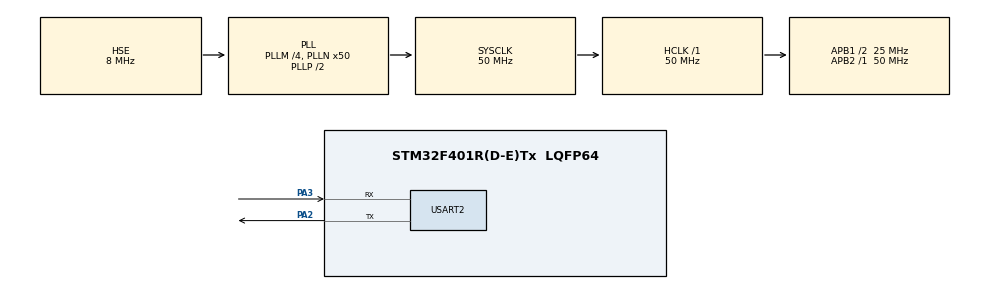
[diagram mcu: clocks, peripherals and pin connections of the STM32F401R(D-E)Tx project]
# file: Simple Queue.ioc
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FREERTOS.Tasks01=defaultTask,0,128,StartDefaultTask,Default,NULL,Dynamic,NULL,NULL
Mcu.Family=STM32F4
Mcu.Name=STM32F401R(D-E)Tx
Mcu.Package=LQFP64
NVIC.PriorityGroup=NVIC_PRIORITYGROUP_4
NVIC.TIM5_IRQn=true\:15\:0\:false\:false\:true\:false\:false\:true\:true
NVIC.TimeBase=TIM5_IRQn
NVIC.TimeBaseIP=TIM5
NVIC.USART2_IRQn=true\:5\:0\:false\:false\:true\:true\:true\:true\:true
PA2.Mode=Asynchronous
PA2.Signal=USART2_TX
PA3.Mode=Asynchronous
PA3.Signal=USART2_RX
PH0\ -\ OSC_IN.Mode=HSE-External-Oscillator
PH0\ -\ OSC_IN.Signal=RCC_OSC_IN
PH1\ -\ OSC_OUT.Mode=HSE-External-Oscillator
PH1\ -\ OSC_OUT.Signal=RCC_OSC_OUT
ProjectManager.HeapSize=0x200
ProjectManager.StackSize=0x400
ProjectManager.TargetToolchain=STM32CubeIDE
RCC.48MHZClocksFreq_Value=25000000
RCC.AHBFreq_Value=50000000
RCC.APB1CLKDivider=RCC_HCLK_DIV2
RCC.APB1Freq_Value=25000000
RCC.APB1TimFreq_Value=50000000
RCC.APB2Freq_Value=50000000
RCC.APB2TimFreq_Value=50000000
RCC.CortexFreq_Value=50000000
RCC.HCLKFreq_Value=50000000
RCC.HSE_VALUE=8000000
RCC.HSI_VALUE=16000000
RCC.LSE_VALUE=32768
RCC.PLLM=4
RCC.PLLN=50
RCC.PLLSourceVirtual=RCC_PLLSOURCE_HSE
RCC.SYSCLKFreq_VALUE=50000000
RCC.SYSCLKSource=RCC_SYSCLKSOURCE_PLLCLK
RCC.VCOOutputFreq_Value=100000000
USART2.VirtualMode=VM_ASYNC
VP_FREERTOS_VS_CMSIS_V1.Mode=CMSIS_V1
VP_SYS_VS_tim5.Mode=TIM5
board=custom

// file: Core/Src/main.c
/* USER CODE BEGIN Header */
/**
 ******************************************************************************
 * @file           : main.c
 * @brief          : Main program body
 ******************************************************************************
 * @attention
 *
 * Copyright (c) 2025 STMicroelectronics.
 * All rights reserved.
 *
 * This software is licensed under terms that can be found in the LICENSE file
 * in the root directory of this software component.
 * If no LICENSE file comes with this software, it is provided AS-IS.
 *
 ******************************************************************************
 */
/* USER CODE END Header */
#include "main.h"
//#include "cmsis_os.h"

/* USER CODE BEGIN Includes */
#include "FreeRTOS.h"
#include "task.h"
#include "timers.h"
#include "queue.h"
#include "semphr.h"
#include "event_groups.h"

#include "string.h"
#include "stdio.h"
/* USER CODE END Includes */

UART_HandleTypeDef huart2;

/* USER CODE BEGIN PV */
uint8_t Rx_data;
/* USER CODE END PV */

void SystemClock_Config(void);
static void MX_GPIO_Init(void);
static void MX_USART2_UART_Init(void);

xTaskHandle Sender_HPT_Handler;
xTaskHandle Sender_LPT_Handler;
xTaskHandle Receiver_Handler;

/**************** QUEUE HANDLER ***********************/
xQueueHandle SimpleQueue;

void Sender_HPT_Task (void *argument);
void Sender_LPT_Task (void *argument);
void Receiver_Task (void *argument);
int main(void)
{

	/* MCU Configuration--------------------------------------------------------*/

	/* Reset of all peripherals, Initializes the Flash interface and the Systick. */
	HAL_Init();

	/* USER	 CODE BEGIN Init */

	/* USER CODE END Init */

	/* Configure the system clock */
	SystemClock_Config();

	/* Initialize all configured peripherals */
	MX_GPIO_Init();
	MX_USART2_UART_Init();
	/************************* Create Integer Queue ****************************/
	SimpleQueue = xQueueCreate(5, sizeof (int));
	if (SimpleQueue == 0)  // Queue not created
	{
		char *str = "Unable to create Integer Queue\n\n";
		HAL_UART_Transmit(&huart2, (uint8_t *)str, strlen (str), HAL_MAX_DELAY);
	}
	else
	{
		char *str = "Integer Queue Created successfully\n\n";
		HAL_UART_Transmit(&huart2, (uint8_t *)str, strlen (str), HAL_MAX_DELAY);
	}
	/* We should never get here as control is now taken by the scheduler */
	xTaskCreate(Sender_HPT_Task, "HPT_SEND", 128, NULL, 3, &Sender_HPT_Handler);
	xTaskCreate(Sender_LPT_Task, "LPT_SEND", 128, (void *)111, 2, &Sender_LPT_Handler);
	xTaskCreate(Receiver_Task, "Receiver", 128, NULL, 1, &Receiver_Handler);
	/* Infinite loop */

	HAL_UART_Receive_IT(&huart2, &Rx_data, 1);

	vTaskStartScheduler();
	while (1)
	{

	}
}

void Sender_HPT_Task (void *argument)
{
	int i=222;
	uint32_t TickDelay = pdMS_TO_TICKS(2000);
	while (1)
	{
		if (xQueueSend(SimpleQueue, &i, portMAX_DELAY) == pdPASS)
		{
			char *str2 = " Successfully sent the number to the queue\nLeaving SENDER_HPT Task\n\n\n";
			HAL_UART_Transmit(&huart2, (uint8_t *)str2, strlen (str2), HAL_MAX_DELAY);
		}
		vTaskDelay(TickDelay);
	}
}

void Sender_LPT_Task (void *argument)
{
	int ToSend;
	uint32_t TickDelay = pdMS_TO_TICKS(1000);
	while (1)
	{
		ToSend = (int) argument;
		if (xQueueSend(SimpleQueue, &ToSend, portMAX_DELAY) == pdPASS)
		{
			char *str2 = " Successfully sent the number to the queue\nLeaving SENDER_LPT Task\n\n\n";
			HAL_UART_Transmit(&huart2, (uint8_t *)str2, strlen (str2), HAL_MAX_DELAY);
		}
		vTaskDelay(TickDelay);
	}
}

void Receiver_Task (void *argument)
{
	int received=0;
	uint32_t TickDelay = pdMS_TO_TICKS(3000);
	while (1)
	{
		char str[100];
//		strcpy(str, "Entered the RECEIVER TASK\N about to RECEIVE a number from the queue\n\n");
		if (xQueueReceive(SimpleQueue, &received, portMAX_DELAY) != pdTRUE)
		{
			HAL_UART_Transmit(&huart2, (uint8_t *)"Error in Receiving from Queue\n\n", 31, 1000);
		}
		else
		{
			sprintf(str, "Successfully RECEIVED the number %d to the queue\nLeaving RECEIVER Task\n\n\n",received);
			HAL_UART_Transmit(&huart2, (uint8_t *)str, strlen (str), HAL_MAX_DELAY);
		}
		vTaskDelay(TickDelay);
	}
}

void SystemClock_Config(void)
{
	RCC_OscInitTypeDef RCC_OscInitStruct = {0};
	RCC_ClkInitTypeDef RCC_ClkInitStruct = {0};

	/** Configure the main internal regulator output voltage
	 */
	__HAL_RCC_PWR_CLK_ENABLE();
	__HAL_PWR_VOLTAGESCALING_CONFIG(PWR_REGULATOR_VOLTAGE_SCALE2);

	/** Initializes the RCC Oscillators according to the specified parameters
	 * in the RCC_OscInitTypeDef structure.
	 */
	RCC_OscInitStruct.OscillatorType = RCC_OSCILLATORTYPE_HSE;
	RCC_OscInitStruct.HSEState = RCC_HSE_ON;
	RCC_OscInitStruct.PLL.PLLState = RCC_PLL_ON;
	RCC_OscInitStruct.PLL.PLLSource = RCC_PLLSOURCE_HSE;
	RCC_OscInitStruct.PLL.PLLM = 4;
	RCC_OscInitStruct.PLL.PLLN = 50;
	RCC_OscInitStruct.PLL.PLLP = RCC_PLLP_DIV2;
	RCC_OscInitStruct.PLL.PLLQ = 4;
	if (HAL_RCC_OscConfig(&RCC_OscInitStruct) != HAL_OK)
	{
		Error_Handler();
	}

	/** Initializes the CPU, AHB and APB buses clocks
	 */
	RCC_ClkInitStruct.ClockType = RCC_CLOCKTYPE_HCLK|RCC_CLOCKTYPE_SYSCLK
			|RCC_CLOCKTYPE_PCLK1|RCC_CLOCKTYPE_PCLK2;
	RCC_ClkInitStruct.SYSCLKSource = RCC_SYSCLKSOURCE_PLLCLK;
	RCC_ClkInitStruct.AHBCLKDivider = RCC_SYSCLK_DIV1;
	RCC_ClkInitStruct.APB1CLKDivider = RCC_HCLK_DIV2;
	RCC_ClkInitStruct.APB2CLKDivider = RCC_HCLK_DIV1;

	if (HAL_RCC_ClockConfig(&RCC_ClkInitStruct, FLASH_LATENCY_1) != HAL_OK)
	{
		Error_Handler();
	}
}

static void MX_USART2_UART_Init(void)
{

	huart2.Instance = USART2;
	huart2.Init.BaudRate = 115200;
	huart2.Init.WordLength = UART_WORDLENGTH_8B;
	huart2.Init.StopBits = UART_STOPBITS_1;
	huart2.Init.Parity = UART_PARITY_NONE;
	huart2.Init.Mode = UART_MODE_TX_RX;
	huart2.Init.HwFlowCtl = UART_HWCONTROL_NONE;
	huart2.Init.OverSampling = UART_OVERSAMPLING_16;
	if (HAL_UART_Init(&huart2) != HAL_OK)
	{
		Error_Handler();
	}

}

static void MX_GPIO_Init(void)
{

	/* GPIO Ports Clock Enable */
	__HAL_RCC_GPIOH_CLK_ENABLE();
	__HAL_RCC_GPIOA_CLK_ENABLE();

}

void HAL_TIM_PeriodElapsedCallback(TIM_HandleTypeDef *htim)
{
	if (htim->Instance == TIM5)
	{
		HAL_IncTick();
	}
}

void Error_Handler(void)
{
	__disable_irq();
	while (1)
	{
	}
}
